VERSION ""

NS_ :

BS_:

BU_: DEBUG BMS DCM FSM PDM DIM

BO_ 100 BMS_HEARTBEAT: 1 BMS
SG_ DUMMY_VARIABLE : 0|1@1+ (1,0) [0|1] "" FSM,DCM,PDM,DIM,INV

BO_ 101 BMS_CAN_FIFO_OVERFLOW: 8 BMS
SG_ tx_overflow_count : 0|32@1+ (1,0) [0|4294967295] "" DEBUG
SG_ rx_overflow_count : 32|32@1+ (1,0) [0|4294967295] "" DEBUG

BO_ 102 BMS_STARTUP: 0 BMS

BO_ 103 BMS_WATCHDOG_TIMEOUT : 8 BMS
SG_ TASK_NAME : 0|64@1+ (1,0) [0|0] "" DEBUG

BO_ 104 BMS_NON_CRITICAL_ERRORS: 8 BMS
SG_ STACK_WATERMARK_ABOVE_THRESHOLD_TASK1HZ : 0|1@1+ (1,0) [0|1] "" DEBUG
SG_ STACK_WATERMARK_ABOVE_THRESHOLD_TASK1KHZ : 1|1@1+ (1,0) [0|1] "" DEBUG
SG_ STACK_WATERMARK_ABOVE_THRESHOLD_TASKCANRX : 2|1@1+ (1,0) [0|1] "" DEBUG
SG_ STACK_WATERMARK_ABOVE_THRESHOLD_TASKCANTX : 3|1@1+ (1,0) [0|1] "" DEBUG
SG_ WATCHDOG_TIMEOUT : 4|1@1+ (1,0) [0|1] "" DEBUG
SG_ SEGMENT_0_VOLTAGE_OUT_OF_RANGE : 6|2@1+ (1,0) [0|2] "" DEBUG
SG_ SEGMENT_1_VOLTAGE_OUT_OF_RANGE : 8|2@1+ (1,0) [0|2] "" DEBUG
SG_ SEGMENT_2_VOLTAGE_OUT_OF_RANGE : 10|2@1+ (1,0) [0|2] "" DEBUG
SG_ SEGMENT_3_VOLTAGE_OUT_OF_RANGE : 12|2@1+ (1,0) [0|2] "" DEBUG
SG_ SEGMENT_4_VOLTAGE_OUT_OF_RANGE : 14|2@1+ (1,0) [0|2] "" DEBUG
SG_ SEGMENT_5_VOLTAGE_OUT_OF_RANGE : 16|2@1+ (1,0) [0|2] "" DEBUG
SG_ PACK_VOLTAGE_OUT_OF_RANGE : 18|2@1+ (1,0) [0|2] "" DEBUG
SG_ AVERAGE_CELL_VOLTAGE_OUT_OF_RANGE : 20|2@1+ (1,0) [0|2] "" DEBUG
SG_ CELL_MONITOR_0_DIE_TEMP_OUT_OF_RANGE : 22|2@1+ (1,0) [0|2] "" DEBUG
SG_ CELL_MONITOR_1_DIE_TEMP_OUT_OF_RANGE : 24|2@1+ (1,0) [0|2] "" DEBUG
SG_ CELL_MONITOR_2_DIE_TEMP_OUT_OF_RANGE : 26|2@1+ (1,0) [0|2] "" DEBUG
SG_ CELL_MONITOR_3_DIE_TEMP_OUT_OF_RANGE : 28|2@1+ (1,0) [0|2] "" DEBUG
SG_ CELL_MONITOR_4_DIE_TEMP_OUT_OF_RANGE : 30|2@1+ (1,0) [0|2] "" DEBUG
SG_ CELL_MONITOR_5_DIE_TEMP_OUT_OF_RANGE : 32|2@1+ (1,0) [0|2] "" DEBUG
SG_ ITMP_CHARGER_HAS_OVERFLOW : 34|1@1+ (1,0) [0|1] "" DEBUG

BO_ 105 BMS_IMD: 8 BMS
SG_ Condition M : 0|3@1+ (1,0) [0|6] "" DEBUG
SG_ Seconds_Since_Power_On : 3|16@1+ (1,0) [0|255] "Seconds" DEBUG
SG_ Valid_Duty_Cycle : 19|1@1+ (1,0) [0|1] "" DEBUG
SG_ Insulation_Measurement_DCP_10Hz m1 : 20|16@1+ (1,0) [0|65535] "kOhm" DEBUG
SG_ Insulation_Measurement_DCP_20Hz m2 : 20|16@1+ (1,0) [0|65535] "kOhm" DEBUG
SG_ Speed_Start_Status_30Hz m3 : 20|16@1+ (1,0) [0|65535] "" DEBUG
SG_ OK_HS : 36|1@1+ (1,0) [0|1] "" DIM

BO_ 106 BMS_IMD_PWM_OUTPUT : 8 BMS
SG_ Duty_Cycle : 0|32@1- (1,0) [0|1E2] "%" DEBUG
SG_ Frequency : 32|32@1- (1,0) [0|1E4] "Hz" DEBUG

BO_ 107 BMS_STATE_MACHINE : 1 BMS
SG_ State : 0|8@1+ (1,0) [0|255] "" DEBUG

BO_ 108 BMS_STATE_OF_CHARGE: 4 BMS
SG_ State_Of_Charge : 0|32@1- (1,0) [0|1E2] "%" DIM

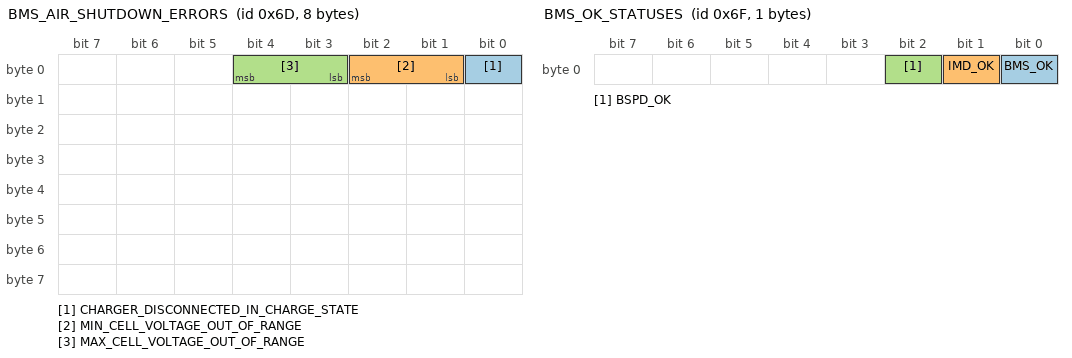
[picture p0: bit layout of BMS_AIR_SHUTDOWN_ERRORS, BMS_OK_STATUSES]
BO_ 109 BMS_AIR_SHUTDOWN_ERRORS: 8 BMS
SG_ CHARGER_DISCONNECTED_IN_CHARGE_STATE : 0|1@1+ (1,0) [0|1] "" DEBUG
SG_ MIN_CELL_VOLTAGE_OUT_OF_RANGE : 1|2@1+ (1,0) [0|2] "" DEBUG
SG_ MAX_CELL_VOLTAGE_OUT_OF_RANGE : 3|2@1+ (1,0) [0|2] "" DEBUG

BO_ 110 BMS_CHARGER: 1 BMS
SG_ Is_Connected : 0|1@1+ (1,0) [0|1] "" DEBUG

BO_ 111 BMS_OK_STATUSES: 1 BMS
SG_ BMS_OK : 0|1@1+ (1,0) [0|1] "" DEBUG
SG_ IMD_OK : 1|1@1+ (1,0) [0|1] "" DEBUG
SG_ BSPD_OK : 2|1@1+ (1,0) [0|1] "" DEBUG

BO_ 112 BMS_AIR_STATES: 1 BMS
SG_ AIR_POSITIVE : 0|1@1+ (1,0) [0|1] "" FSM,DCM,PDM
SG_ AIR_NEGATIVE : 1|1@1+ (1,0) [0|1] "" FSM,DCM,PDM

BO_ 113 BMS_MOTOR_SHUTDOWN_ERRORS: 8 BMS
SG_ DUMMY_MOTOR_SHUTDOWN : 0|1@1+ (1,0) [0|1] "" DEBUG

BO_ 114 BMS_ACCUMULATOR_MIN_AND_MAX_VOLTAGES: 8 BMS
SG_ MIN_CELL_VOLTAGE : 0|32@1+ (1,0) [3.0|4.20] "V" DEBUG
SG_ MAX_CELL_VOLTAGE : 32|32@1+ (1,0) [3.0|4.20] "V" DEBUG

BO_ 115 BMS_ACCUMULATOR_PACK: 4 BMS
SG_ PACK_VOLTAGE : 0|32@1+ (1,0) [288.0|403.2] "V" DEBUG

BO_ 116 BMS_ACCUMULATOR_AVERAGE_CELL: 4 BMS
SG_ AVERAGE_CELL_VOLTAGE : 0|32@1+ (1,0) [3.0|4.20] "V" DEBUG

BO_ 117 BMS_ACCUMULATOR_SEGMENT_0: 4 BMS
SG_ SEGMENT_0_VOLTAGE : 0|32@1+ (1,0) [48.0|67.2] "V" DEBUG

BO_ 118 BMS_ACCUMULATOR_SEGMENT_1: 4 BMS
SG_ SEGMENT_1_VOLTAGE : 0|32@1+ (1,0) [48.0|67.2] "V" DEBUG

BO_ 119 BMS_ACCUMULATOR_SEGMENT_2: 4 BMS
SG_ SEGMENT_2_VOLTAGE : 0|32@1+ (1,0) [48.0|67.2] "V" DEBUG

BO_ 120 BMS_ACCUMULATOR_SEGMENT_3: 4 BMS
SG_ SEGMENT_3_VOLTAGE : 0|32@1+ (1,0) [48.0|67.2] "V" DEBUG

BO_ 121 BMS_ACCUMULATOR_SEGMENT_4: 4 BMS
SG_ SEGMENT_4_VOLTAGE : 0|32@1+ (1,0) [48.0|67.2] "V" DEBUG

BO_ 122 BMS_ACCUMULATOR_SEGMENT_5: 4 BMS
SG_ SEGMENT_5_VOLTAGE : 0|32@1+ (1,0) [48.0|67.2] "V" DEBUG

BO_ 123 BMS_CELL_MONITOR_0: 4 BMS
SG_ CELL_MONITOR_0_DIE_TEMPERATURE : 0|32@1+ (1,0) [0.0|120.0] "degC" DEBUG

BO_ 124 BMS_CELL_MONITOR_1: 4 BMS
SG_ CELL_MONITOR_1_DIE_TEMPERATURE : 0|32@1+ (1,0) [0.0|120.0] "degC" DEBUG

BO_ 125 BMS_CELL_MONITOR_2: 4 BMS
SG_ CELL_MONITOR_2_DIE_TEMPERATURE : 0|32@1+ (1,0) [0.0|120.0] "degC" DEBUG

BO_ 126 BMS_CELL_MONITOR_3: 4 BMS
SG_ CELL_MONITOR_3_DIE_TEMPERATURE : 0|32@1+ (1,0) [0.0|120.0] "degC" DEBUG

BO_ 127 BMS_CELL_MONITOR_4: 4 BMS
SG_ CELL_MONITOR_4_DIE_TEMPERATURE : 0|32@1+ (1,0) [0.0|120.0] "degC" DEBUG

BO_ 128 BMS_CELL_MONITOR_5: 4 BMS
SG_ CELL_MONITOR_5_DIE_TEMPERATURE : 0|32@1+ (1,0) [0.0|120.0] "degC" DEBUG

BO_ 129 BMS_MAX_CELL_MONITOR: 4 BMS
SG_ MAX_CELL_MONITOR_DIE_TEMPERATURE : 0|32@1+ (1,0) [0.0|120.0] "degC" DEBUG

BO_ 200 DCM_HEARTBEAT: 1 DCM
SG_ DUMMY_VARIABLE : 0|1@1+ (1,0) [0|1] "" BMS

BO_ 201 DCM_CAN_FIFO_OVERFLOW: 8 DCM
SG_ tx_overflow_count : 0|32@1+ (1,0) [0|4294967295] "" DEBUG
SG_ rx_overflow_count : 32|32@1+ (1,0) [0|4294967295] "" DEBUG

BO_ 202 DCM_STARTUP: 0 DCM

BO_ 203 DCM_WATCHDOG_TIMEOUT : 8 DCM
SG_ TASK_NAME : 0|64@1+ (1,0) [0|0] "" DEBUG

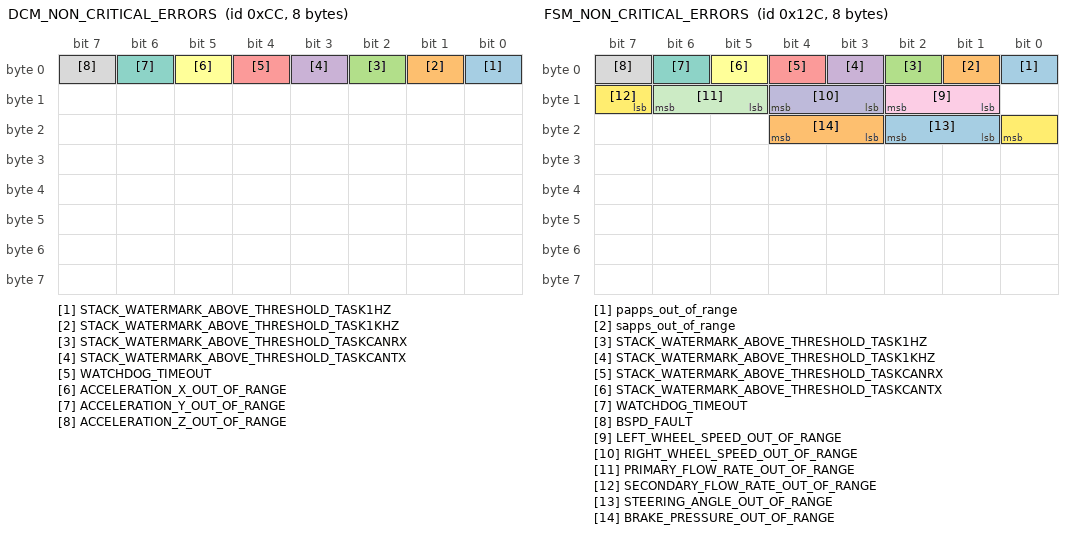
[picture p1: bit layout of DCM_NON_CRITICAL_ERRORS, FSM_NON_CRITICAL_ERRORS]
BO_ 204 DCM_NON_CRITICAL_ERRORS: 8 DCM
SG_ STACK_WATERMARK_ABOVE_THRESHOLD_TASK1HZ : 0|1@1+ (1,0) [0|1] "" DEBUG
SG_ STACK_WATERMARK_ABOVE_THRESHOLD_TASK1KHZ : 1|1@1+ (1,0) [0|1] "" DEBUG
SG_ STACK_WATERMARK_ABOVE_THRESHOLD_TASKCANRX : 2|1@1+ (1,0) [0|1] "" DEBUG
SG_ STACK_WATERMARK_ABOVE_THRESHOLD_TASKCANTX : 3|1@1+ (1,0) [0|1] "" DEBUG
SG_ WATCHDOG_TIMEOUT : 4|1@1+ (1,0) [0|1] "" DEBUG
SG_ ACCELERATION_X_OUT_OF_RANGE : 5|1@1+ (1,0) [0|1] "" DEBUG
SG_ ACCELERATION_Y_OUT_OF_RANGE : 6|1@1+ (1,0) [0|1] "" DEBUG
SG_ ACCELERATION_Z_OUT_OF_RANGE : 7|1@1+ (1,0) [0|1] "" DEBUG

BO_ 205 DCM_STATE_MACHINE : 1 DCM
SG_ State : 0|8@1+ (1,0) [0|255] "" DEBUG

BO_ 206 DCM_TORQUE_REQUEST : 4 DCM
SG_ Torque_Request : 0|32@1+ (1,0) [-3.4E038|3.4E038] "" LOGGER,INV

BO_ 207 DCM_AIR_SHUTDOWN_ERRORS: 8 DCM
SG_ DUMMY_AIR_SHUTDOWN : 0|1@1+ (1,0) [0|1] "" DEBUG

BO_ 208 DCM_MOTOR_SHUTDOWN_ERRORS: 8 DCM
SG_ DUMMY_MOTOR_SHUTDOWN : 0|1@1+ (1,0) [0|1] "" DEBUG

BO_ 209 DCM_ACCELERATION_X: 4 DCM
SG_ ACCELERATION_X : 0|32@1+ (1,0) [-30.00|30.00] "m/s^2" DEBUG

BO_ 210 DCM_ACCELERATION_Y: 4 DCM
SG_ ACCELERATION_Y : 0|32@1+ (1,0) [-30.00|30.00] "m/s^2" DEBUG

BO_ 211 DCM_ACCELERATION_Z: 4 DCM
SG_ ACCELERATION_Z : 0|32@1+ (1,0) [-30.00|30.00] "m/s^2" DEBUG

BO_ 300 FSM_NON_CRITICAL_ERRORS: 8 FSM
SG_ papps_out_of_range : 0|1@1+ (1,0) [0|1] "" DEBUG
SG_ sapps_out_of_range : 1|1@1+ (1,0) [0|1] "" DEBUG
SG_ STACK_WATERMARK_ABOVE_THRESHOLD_TASK1HZ : 2|1@1+ (1,0) [0|1] "" DEBUG
SG_ STACK_WATERMARK_ABOVE_THRESHOLD_TASK1KHZ : 3|1@1+ (1,0) [0|1] "" DEBUG
SG_ STACK_WATERMARK_ABOVE_THRESHOLD_TASKCANRX : 4|1@1+ (1,0) [0|1] "" DEBUG
SG_ STACK_WATERMARK_ABOVE_THRESHOLD_TASKCANTX : 5|1@1+ (1,0) [0|1] "" DEBUG
SG_ WATCHDOG_TIMEOUT : 6|1@1+ (1,0) [0|1] "" DEBUG
SG_ BSPD_FAULT : 7|1@1+ (1,0) [0|1] "" DIM
SG_ LEFT_WHEEL_SPEED_OUT_OF_RANGE: 9|2@1+ (1,0) [0|2] "" DEBUG
SG_ RIGHT_WHEEL_SPEED_OUT_OF_RANGE: 11|2@1+ (1,0) [0|2] ""  DEBUG
SG_ PRIMARY_FLOW_RATE_OUT_OF_RANGE: 13|2@1+ (1,0) [0|2] "" DEBUG
SG_ SECONDARY_FLOW_RATE_OUT_OF_RANGE: 15|2@1+ (1,0) [0|2] "" DEBUG
SG_ STEERING_ANGLE_OUT_OF_RANGE: 17|2@1+ (1,0) [0|2] "" DEBUG
SG_ BRAKE_PRESSURE_OUT_OF_RANGE: 19|2@1+ (1,0) [0|2] "" DEBUG

BO_ 301 FSM_HEARTBEAT: 1 FSM
SG_ DUMMY_VARIABLE : 0|1@1+ (1,0) [0|1] "" BMS

BO_ 302 FSM_CAN_FIFO_OVERFLOW: 8 FSM
SG_ tx_overflow_count : 0|32@1+ (1,0) [0|1] "" DEBUG
SG_ rx_overflow_count : 32|32@1+ (1,0) [0|1] "" DEBUG

BO_ 303 FSM_STARTUP: 0 FSM

BO_ 304 FSM_WATCHDOG_TIMEOUT : 8 FSM
SG_ TASK_NAME : 0|64@1+ (1,0) [0|0] "" DEBUG

BO_ 305 FSM_STATE_MACHINE : 1 FSM
SG_ State : 0|8@1+ (1,0) [0|255] "" DEBUG

BO_ 306 FSM_AIR_SHUTDOWN: 0 FSM

BO_ 307 FSM_FLOW_METER: 8 FSM
SG_ Primary_Flow_Rate : 0|32@1+ (1,0) [0|100] "L/min" DEBUG
SG_ Secondary_Flow_Rate : 32|32@1+ (1,0) [0|100] "L/min" DEBUG

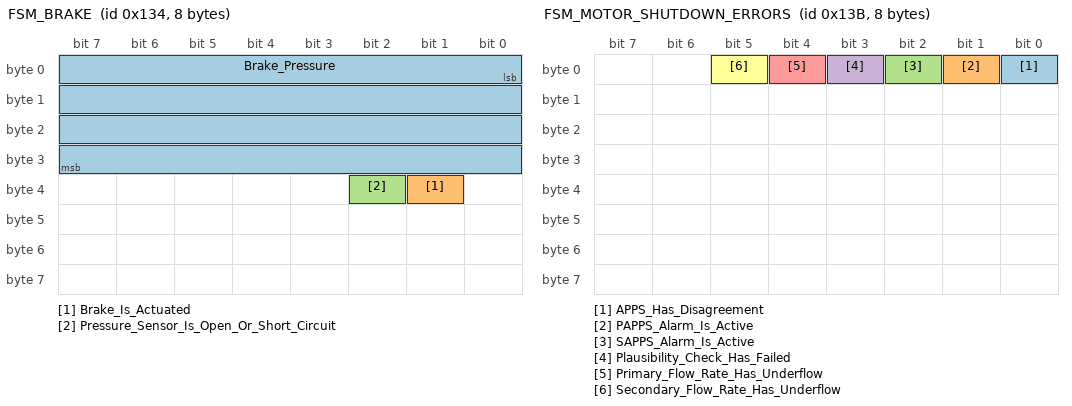
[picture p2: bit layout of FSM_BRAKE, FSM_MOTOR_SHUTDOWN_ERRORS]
BO_ 308 FSM_BRAKE: 8 FSM
SG_ Brake_Pressure: 0|32@1+ (1,0) [0|2500] "psi" DEBUG
SG_ Brake_Is_Actuated: 33|1@1+ (1,0) [0|1] "" DCM
SG_ Pressure_Sensor_Is_Open_Or_Short_Circuit: 34|1@1+ (1,0) [0|1] "" DEBUG

BO_ 309 FSM_WHEEL_SPEED_SENSOR: 8 FSM
SG_ Left_Wheel_Speed : 0|32@1+ (1,0) [0|150] "km/h" DCM
SG_ Right_Wheel_Speed : 32|32@1+ (1,0) [0|150] "km/h" DCM

BO_ 310 FSM_AIR_SHUTDOWN_ERRORS: 8 FSM
SG_ DUMMY_AIR_SHUTDOWN : 0|1@1+ (1,0) [0|1] "" DEBUG

BO_ 311 FSM_STEERING_ANGLE_SENSOR: 4 FSM
SG_ Steering_Angle : 0|32@1+ (1,0) [-110|110] "deg" DCM

BO_ 313 FSM_PRIMARY_APPS: 4 FSM
SG_ Papps_Mapped_Pedal_Percentage : 0|32@1+ (1,0) [0|100] "%" DEBUG

BO_ 314 FSM_SECONDARY_APPS: 4 FSM
SG_ Sapps_Mapped_Pedal_Percentage : 0|32@1+ (1,0) [0|100] "%" DEBUG

BO_ 315 FSM_MOTOR_SHUTDOWN_ERRORS: 8 FSM
SG_ APPS_Has_Disagreement : 0|1@1+ (1,0) [0|1] "" DEBUG
SG_ PAPPS_Alarm_Is_Active : 1|1@1+ (1,0) [0|1] "" DEBUG
SG_ SAPPS_Alarm_Is_Active : 2|1@1+ (1,0) [0|1] "" DEBUG
SG_ Plausibility_Check_Has_Failed : 3|1@1+ (1,0) [0|1] "" DEBUG
SG_ Primary_Flow_Rate_Has_Underflow : 4|1@1+ (1,0) [0|1] "" DEBUG
SG_ Secondary_Flow_Rate_Has_Underflow : 5|1@1+ (1,0) [0|1] "" DEBUG

BO_ 316 FSM_PEDAL_POSITION: 4 FSM
SG_ Mapped_Pedal_Percentage: 0|32@1+ (1,0) [0|100] "%" DCM

BO_ 400 PDM_NON_CRITICAL_ERRORS: 8 PDM
SG_ MISSING_HEARTBEAT : 0|1@1+ (1,0) [0|1] "" DEBUG
SG_ BOOST_PGOOD_FAULT : 1|1@1+ (1,0) [0|1] "" DEBUG
SG_ CHARGER_FAULT : 3|1@1+ (1,0) [0|1] "" DEBUG
SG_ EFUSE_FAULT : 4|1@1+ (1,0) [0|1] "" DEBUG
SG_ STACK_WATERMARK_ABOVE_THRESHOLD_TASK1HZ : 5|1@1+ (1,0) [0|1] "" DEBUG
SG_ STACK_WATERMARK_ABOVE_THRESHOLD_TASK1KHZ : 6|1@1+ (1,0) [0|1] "" DEBUG
SG_ STACK_WATERMARK_ABOVE_THRESHOLD_TASKCANRX : 7|1@1+ (1,0) [0|1] "" DEBUG
SG_ STACK_WATERMARK_ABOVE_THRESHOLD_TASKCANTX : 8|1@1+ (1,0) [0|1] "" DEBUG
SG_ WATCHDOG_TIMEOUT : 9|1@1+ (1,0) [0|1] "" DEBUG
SG_ VBAT_VOLTAGE_OUT_OF_RANGE : 10|2@1+ (1,0) [0|2] "" DEBUG
SG_ _24V_AUX_VOLTAGE_OUT_OF_RANGE : 12|2@1+ (1,0) [0|2] "" DEBUG
SG_ _24V_ACC_VOLTAGE_OUT_OF_RANGE : 14|2@1+ (1,0) [0|2] "" DEBUG
SG_ AUX1_CURRENT_OUT_OF_RANGE : 16|2@1+ (1,0) [0|2] "" DEBUG
SG_ AUX2_CURRENT_OUT_OF_RANGE : 18|2@1+ (1,0) [0|2] "" DEBUG
SG_ LEFT_INVERTER_CURRENT_OUT_OF_RANGE : 20|2@1+ (1,0) [0|2] "" DEBUG
SG_ RIGHT_INVERTER_CURRENT_OUT_OF_RANGE : 22|2@1+ (1,0) [0|2] "" DEBUG
SG_ ENERGY_METER_CURRENT_OUT_OF_RANGE : 24|2@1+ (1,0) [0|2] "" DEBUG
SG_ CAN_CURRENT_OUT_OF_RANGE : 26|2@1+ (1,0) [0|2] "" DEBUG
SG_ AIR_SHUTDOWN_CURRENT_OUT_OF_RANGE : 28|2@1+ (1,0) [0|2] "" DEBUG

BO_ 401 PDM_HEARTBEAT: 1 PDM
SG_ DUMMY_VARIABLE : 0|1@1+ (1,0) [0|1] "" BMS

BO_ 402 PDM_CAN_FIFO_OVERFLOW: 8 PDM
SG_ tx_overflow_count : 0|32@1+ (1,0) [0|4294967295] "" DEBUG
SG_ rx_overflow_count : 32|32@1+ (1,0) [0|4294967295] "" DEBUG

BO_ 403 PDM_STARTUP: 0 PDM

BO_ 404 PDM_AIR_SHUTDOWN_ERRORS: 8 PDM
SG_ DUMMY_AIR_SHUTDOWN : 0|1@1+ (1,0) [0|1] "" DEBUG

BO_ 405 PDM_MOTOR_SHUTDOWN_ERRORS: 8 PDM
SG_ DUMMY_MOTOR_SHUTDOWN : 0|1@1+ (1,0) [0|1] "" DEBUG

BO_ 406 PDM_AUX1_AUX2_CURRENT: 8 PDM
SG_ Auxiliary1_Current : 0|32@1- (1,0) [0|1E2] "A" DEBUG
SG_ Auxiliary2_Current : 32|32@1- (1,0) [0|1E2] "A" DEBUG

BO_ 407 PDM_ENERGY_METER_CURRENT: 8 PDM
SG_ Energy_Meter_Current : 0|32@1- (1,0) [0|1E2] "A" DEBUG
SG_ Unused : 32|32@1- (1,0) [0|1E2] "A" DEBUG

BO_ 408 PDM_AIRSHDN_CANGLV_CURRENT: 8 PDM
SG_ CAN_Current : 0|32@1- (1,0) [0|1E2] "A" DEBUG
SG_ AIR_Shutdown_Current : 32|32@1- (1,0) [0|1E2] "A" DEBUG

BO_ 409 PDM_INVERTER_CURRENT: 8 PDM
SG_ Left_Inverter_Current : 0|32@1- (1,0) [0|1E2] "A" DEBUG
SG_ Right_Inverter_Current : 32|32@1- (1,0) [0|1E2] "A" DEBUG

BO_ 410 PDM_24V: 8 PDM
SG_ _24V_AUX : 0|32@1- (1,0) [0|1E2] "V" DEBUG
SG_ _24V_ACC: 32|32@1- (1,0) [0|1E2] "V" DEBUG

BO_ 411 PDM_VBAT: 4 PDM
SG_ VBAT : 0|32@1- (1,0) [0|1E2] "V" DEBUG

BO_ 412 PDM_WATCHDOG_TIMEOUT: 8 PDM
SG_ TASK_NAME : 0|64@1+ (1,0) [0|0] "" DEBUG

BO_ 413 PDM_STATE_MACHINE : 1 PDM
SG_ State : 0|8@1+ (1,0) [0|255] "" DEBUG

BO_ 500 DIM_HEARTBEAT: 1 DIM
SG_ DUMMY_VARIABLE : 0|1@1+ (1,0) [0|1] "" FSM,DCM,PDM,BMS

BO_ 501 DIM_CAN_FIFO_OVERFLOW: 8 DIM
SG_ tx_overflow_count : 0|32@1+ (1,0) [0|4294967295] "" DEBUG
SG_ rx_overflow_count : 32|32@1+ (1,0) [0|4294967295] "" DEBUG

BO_ 502 DIM_STARTUP: 0 DIM

BO_ 503 DIM_STATE_MACHINE : 1 DIM
SG_ State : 0|8@1+ (1,0) [0|255] "" DEBUG

BO_ 504 DIM_WATCHDOG_TIMEOUT: 8 DIM
SG_ TASK_NAME : 0|64@1+ (1,0) [0|0] "" DEBUG

BO_ 505 DIM_REGEN_PADDLE: 8 DIM
SG_ Raw_Paddle_Position : 0|32@1+ (1,0) [0|100] "%" DEBUG
SG_ Mapped_Paddle_Position : 32|32@1+ (1,0) [0|100] "%" DCM

BO_ 506 DIM_DRIVE_MODE_SWITCH: 1 DIM
SG_ Drive_Mode : 0|3@1+ (1,0) [0|5] "" DCM

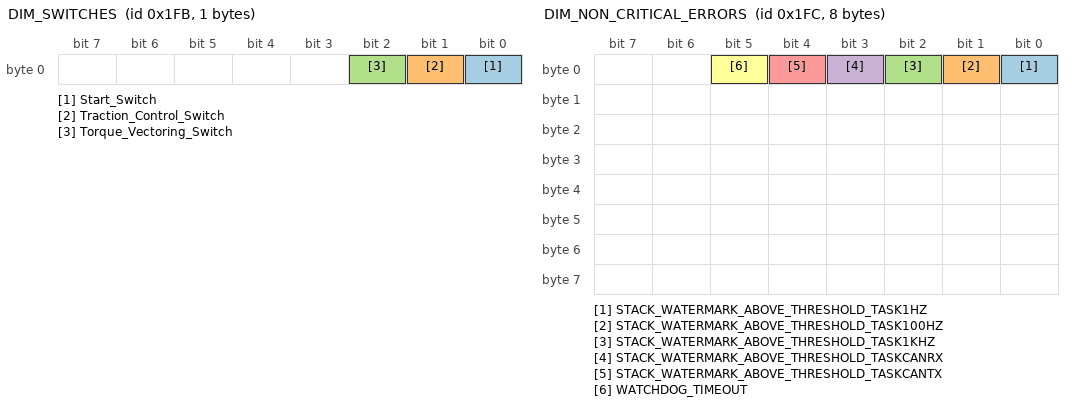
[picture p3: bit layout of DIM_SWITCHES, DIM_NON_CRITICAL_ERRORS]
BO_ 507 DIM_SWITCHES: 1 DIM
SG_ Start_Switch : 0|1@1+ (1,0) [0|1] "" DCM
SG_ Traction_Control_Switch : 1|1@1+ (1,0) [0|1] "" DCM
SG_ Torque_Vectoring_Switch : 2|1@1+ (1,0) [0|1] "" DCM

BO_ 508 DIM_NON_CRITICAL_ERRORS: 8 DIM
SG_ STACK_WATERMARK_ABOVE_THRESHOLD_TASK1HZ : 0|1@1+ (1,0) [0|1] "" LOGGER
SG_ STACK_WATERMARK_ABOVE_THRESHOLD_TASK100HZ : 1|1@1+ (1,0) [0|1] "" LOGGER
SG_ STACK_WATERMARK_ABOVE_THRESHOLD_TASK1KHZ : 2|1@1+ (1,0) [0|1] "" LOGGER
SG_ STACK_WATERMARK_ABOVE_THRESHOLD_TASKCANRX : 3|1@1+ (1,0) [0|1] "" LOGGER
SG_ STACK_WATERMARK_ABOVE_THRESHOLD_TASKCANTX : 4|1@1+ (1,0) [0|1] "" LOGGER
SG_ WATCHDOG_TIMEOUT : 5|1@1+ (1,0) [0|1] "" LOGGER

BO_ 509 DIM_AIR_SHUTDOWN_ERRORS: 8 DIM
SG_ DUMMY_AIR_SHUTDOWN : 0|1@1+ (1,0) [0|1] "" DEBUG

BO_ 510 DIM_MOTOR_SHUTDOWN_ERRORS: 8 DIM
SG_ DUMMY_MOTOR_SHUTDOWN : 0|1@1+ (1,0) [0|1] "" DEBUG

BO_ 600 INV_HEARTBEAT: 1 INV
SG_ DUMMY_VARIABLE : 0|1@1+ (1,0) [0|1] "" FSM,DCM,PDM,BMS,DIM

BO_ 601 INV_CAN_FIFO_OVERFLOW: 8 INV
SG_ tx_overflow_count : 0|32@1+ (1,0) [0|4294967295] "" DEBUG
SG_ rx_overflow_count : 32|32@1+ (1,0) [0|4294967295] "" DEBUG

BO_ 602 INV_STARTUP: 0 INV

BO_ 603 INV_STATE_MACHINE : 2 INV
SG_ State : 0|8@1+ (1,0) [0|255] "" DEBUG
SG_ Command : 8|8@1+ (1,0) [0|255] "" DEBUG

BO_ 604 INV_WATCHDOG_TIMEOUT: 8 INV
SG_ TASK_NAME : 0|64@1+ (1,0) [0|0] "" DEBUG

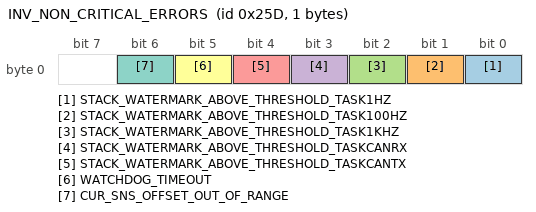
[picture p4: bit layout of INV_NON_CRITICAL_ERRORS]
BO_ 605 INV_NON_CRITICAL_ERRORS: 1 INV
SG_ STACK_WATERMARK_ABOVE_THRESHOLD_TASK1HZ : 0|1@1+ (1,0) [0|1] "" LOGGER
SG_ STACK_WATERMARK_ABOVE_THRESHOLD_TASK100HZ : 1|1@1+ (1,0) [0|1] "" LOGGER
SG_ STACK_WATERMARK_ABOVE_THRESHOLD_TASK1KHZ : 2|1@1+ (1,0) [0|1] "" LOGGER
SG_ STACK_WATERMARK_ABOVE_THRESHOLD_TASKCANRX : 3|1@1+ (1,0) [0|1] "" LOGGER
SG_ STACK_WATERMARK_ABOVE_THRESHOLD_TASKCANTX : 4|1@1+ (1,0) [0|1] "" LOGGER
SG_ WATCHDOG_TIMEOUT : 5|1@1+ (1,0) [0|1] "" LOGGER
SG_ CUR_SNS_OFFSET_OUT_OF_RANGE : 6|1@1+ (1,0) [0|1] "" LOGGER

BO_ 606 INV_AIR_SHUTDOWN_ERRORS: 8 INV
SG_ DUMMY_AIR_SHUTDOWN : 0|1@1+ (1,0) [0|1] "" DEBUG

BO_ 607 INV_MOTOR_SHUTDOWN_ERRORS: 8 INV
SG_ DUMMY_MOTOR_SHUTDOWN : 0|1@1+ (1,0) [0|1] "" DEBUG

BA_DEF_  "BusType" STRING ;
BA_DEF_ BO_  "GenMsgCycleTime" INT 0 65535;
BA_DEF_ SG_  "GenSigStartValue" INT 0 2147483647;

BA_DEF_DEF_  "BusType" "CAN";
BA_DEF_DEF_  "GenMsgCycleTime" 0;
BA_DEF_DEF_  "GenSigStartValue" 0;

BA_ "GenMsgCycleTime" BO_ 100 100;
BA_ "GenMsgCycleTime" BO_ 101 5000;
BA_ "GenMsgCycleTime" BO_ 104 1000;
BA_ "GenMsgCycleTime" BO_ 105 1000;
BA_ "GenMsgCycleTime" BO_ 106 1000;
BA_ "GenMsgCycleTime" BO_ 107 10;
BA_ "GenMsgCycleTime" BO_ 108 10;
BA_ "GenMsgCycleTime" BO_ 109 1000;
BA_ "GenMsgCycleTime" BO_ 110 1000;
BA_ "GenMsgCycleTime" BO_ 111 10;
BA_ "GenMsgCycleTime" BO_ 112 10;
BA_ "GenMsgCycleTime" BO_ 113 1000;
BA_ "GenMsgCycleTime" BO_ 114 10;
BA_ "GenMsgCycleTime" BO_ 115 10;
BA_ "GenMsgCycleTime" BO_ 116 10;
BA_ "GenMsgCycleTime" BO_ 117 10;
BA_ "GenMsgCycleTime" BO_ 118 10;
BA_ "GenMsgCycleTime" BO_ 119 10;
BA_ "GenMsgCycleTime" BO_ 120 10;
BA_ "GenMsgCycleTime" BO_ 121 10;
BA_ "GenMsgCycleTime" BO_ 122 10;
BA_ "GenMsgCycleTime" BO_ 123 1000;
BA_ "GenMsgCycleTime" BO_ 124 1000;
BA_ "GenMsgCycleTime" BO_ 125 1000;
BA_ "GenMsgCycleTime" BO_ 126 1000;
BA_ "GenMsgCycleTime" BO_ 127 1000;
BA_ "GenMsgCycleTime" BO_ 128 1000;
BA_ "GenMsgCycleTime" BO_ 129 1000;
BA_ "GenMsgCycleTime" BO_ 200 100;
BA_ "GenMsgCycleTime" BO_ 201 5000;
BA_ "GenMsgCycleTime" BO_ 204 1000;
BA_ "GenMsgCycleTime" BO_ 205 10;
BA_ "GenMsgCycleTime" BO_ 206 10;
BA_ "GenMsgCycleTime" BO_ 207 1000;
BA_ "GenMsgCycleTime" BO_ 208 1000;
BA_ "GenMsgCycleTime" BO_ 209 10;
BA_ "GenMsgCycleTime" BO_ 210 10;
BA_ "GenMsgCycleTime" BO_ 211 10;
BA_ "GenMsgCycleTime" BO_ 300 1000;
BA_ "GenMsgCycleTime" BO_ 301 100;
BA_ "GenMsgCycleTime" BO_ 302 5000;
BA_ "GenMsgCycleTime" BO_ 305 10;
BA_ "GenMsgCycleTime" BO_ 307 1000;
BA_ "GenMsgCycleTime" BO_ 308 10;
BA_ "GenMsgCycleTime" BO_ 309 10;
BA_ "GenMsgCycleTime" BO_ 310 1000;
BA_ "GenMsgCycleTime" BO_ 311 10;
BA_ "GenMsgCycleTime" BO_ 313 10;
BA_ "GenMsgCycleTime" BO_ 314 10;
BA_ "GenMsgCycleTime" BO_ 315 1000;
BA_ "GenMsgCycleTime" BO_ 316 100;
BA_ "GenMsgCycleTime" BO_ 400 1000;
BA_ "GenMsgCycleTime" BO_ 401 100;
BA_ "GenMsgCycleTime" BO_ 402 5000;
BA_ "GenMsgCycleTime" BO_ 404 1000;
BA_ "GenMsgCycleTime" BO_ 405 1000;
BA_ "GenMsgCycleTime" BO_ 406 1000;
BA_ "GenMsgCycleTime" BO_ 407 1000;
BA_ "GenMsgCycleTime" BO_ 408 1000;
BA_ "GenMsgCycleTime" BO_ 409 1000;
BA_ "GenMsgCycleTime" BO_ 410 1000;
BA_ "GenMsgCycleTime" BO_ 411 1000;
BA_ "GenMsgCycleTime" BO_ 413 10;
BA_ "GenMsgCycleTime" BO_ 500 100;
BA_ "GenMsgCycleTime" BO_ 501 5000;
BA_ "GenMsgCycleTime" BO_ 503 10;
BA_ "GenMsgCycleTime" BO_ 505 10;
BA_ "GenMsgCycleTime" BO_ 506 10;
BA_ "GenMsgCycleTime" BO_ 507 10;
BA_ "GenMsgCycleTime" BO_ 508 1000;
BA_ "GenMsgCycleTime" BO_ 509 1000;
BA_ "GenMsgCycleTime" BO_ 510 1000;
BA_ "GenMsgCycleTime" BO_ 600 100;
BA_ "GenMsgCycleTime" BO_ 601 5000;
BA_ "GenMsgCycleTime" BO_ 603 10;
BA_ "GenMsgCycleTime" BO_ 605 1000;
BA_ "GenMsgCycleTime" BO_ 606 1000;
BA_ "GenMsgCycleTime" BO_ 607 1000;

SIG_VALTYPE_ 106 Duty_Cycle : 1;
SIG_VALTYPE_ 106 Frequency : 1;
SIG_VALTYPE_ 108 State_Of_Charge : 1;
SIG_VALTYPE_ 114 MIN_CELL_VOLTAGE : 1;
SIG_VALTYPE_ 114 MAX_CELL_VOLTAGE : 1;
SIG_VALTYPE_ 115 PACK_VOLTAGE : 1;
SIG_VALTYPE_ 116 AVERAGE_CELL_VOLTAGE : 1;
SIG_VALTYPE_ 117 SEGMENT_0_VOLTAGE : 1;
SIG_VALTYPE_ 118 SEGMENT_1_VOLTAGE : 1;
SIG_VALTYPE_ 119 SEGMENT_2_VOLTAGE : 1;
SIG_VALTYPE_ 120 SEGMENT_3_VOLTAGE : 1;
SIG_VALTYPE_ 121 SEGMENT_4_VOLTAGE : 1;
SIG_VALTYPE_ 122 SEGMENT_5_VOLTAGE : 1;
SIG_VALTYPE_ 123 CELL_MONITOR_0_DIE_TEMPERATURE : 1;
SIG_VALTYPE_ 124 CELL_MONITOR_1_DIE_TEMPERATURE : 1;
SIG_VALTYPE_ 125 CELL_MONITOR_2_DIE_TEMPERATURE : 1;
SIG_VALTYPE_ 126 CELL_MONITOR_3_DIE_TEMPERATURE : 1;
SIG_VALTYPE_ 127 CELL_MONITOR_4_DIE_TEMPERATURE : 1;
SIG_VALTYPE_ 128 CELL_MONITOR_5_DIE_TEMPERATURE : 1;
SIG_VALTYPE_ 129 MAX_CELL_MONITOR_DIE_TEMPERATURE : 1;
SIG_VALTYPE_ 206 Torque_Request : 1;
SIG_VALTYPE_ 209 ACCELERATION_X : 1;
SIG_VALTYPE_ 210 ACCELERATION_Y : 1;
SIG_VALTYPE_ 211 ACCELERATION_Z : 1;
SIG_VALTYPE_ 307 Primary_Flow_Rate: 1;
SIG_VALTYPE_ 307 Secondary_Flow_Rate: 1;
SIG_VALTYPE_ 308 Brake_Pressure: 1;
SIG_VALTYPE_ 309 Left_Wheel_Speed: 1;
SIG_VALTYPE_ 309 Right_Wheel_Speed: 1;
SIG_VALTYPE_ 311 Steering_Angle: 1;
SIG_VALTYPE_ 313 Papps_Mapped_Pedal_Percentage : 1;
SIG_VALTYPE_ 314 Sapps_Mapped_Pedal_Percentage : 1;
SIG_VALTYPE_ 316 Mapped_Pedal_Percentage : 1;
SIG_VALTYPE_ 406 Auxiliary1_Current : 1;
SIG_VALTYPE_ 406 Auxiliary2_Current : 1;
SIG_VALTYPE_ 407 Energy_Meter_Current : 1;
SIG_VALTYPE_ 408 AIR_Shutdown_Current : 1;
SIG_VALTYPE_ 408 CAN_Current : 1;
SIG_VALTYPE_ 409 Left_Inverter_Current : 1;
SIG_VALTYPE_ 409 Right_Inverter_Current : 1;
SIG_VALTYPE_ 410 _24V_AUX : 1;
SIG_VALTYPE_ 410 _24V_ACC : 1;
SIG_VALTYPE_ 411 VBAT : 1;

VAL_ 104 SEGMENT_0_VOLTAGE_OUT_OF_RANGE 0 "OK" 1 "UNDERFLOW" 2 "OVERFLOW";
VAL_ 104 SEGMENT_1_VOLTAGE_OUT_OF_RANGE 0 "OK" 1 "UNDERFLOW" 2 "OVERFLOW";
VAL_ 104 SEGMENT_2_VOLTAGE_OUT_OF_RANGE 0 "OK" 1 "UNDERFLOW" 2 "OVERFLOW";
VAL_ 104 SEGMENT_3_VOLTAGE_OUT_OF_RANGE 0 "OK" 1 "UNDERFLOW" 2 "OVERFLOW";
VAL_ 104 SEGMENT_4_VOLTAGE_OUT_OF_RANGE 0 "OK" 1 "UNDERFLOW" 2 "OVERFLOW";
VAL_ 104 SEGMENT_5_VOLTAGE_OUT_OF_RANGE 0 "OK" 1 "UNDERFLOW" 2 "OVERFLOW";
VAL_ 104 PACK_VOLTAGE_OUT_OF_RANGE 0 "OK" 1 "UNDERFLOW" 2 "OVERFLOW";
VAL_ 104 AVERAGE_CELL_VOLTAGE_OUT_OF_RANGE 0 "OK" 1 "UNDERFLOW" 2 "OVERFLOW";
VAL_ 104 CELL_MONITOR_0_DIE_TEMP_OUT_OF_RANGE 0 "OK" 1 "UNDERFLOW" 2 "OVERFLOW";
VAL_ 104 CELL_MONITOR_1_DIE_TEMP_OUT_OF_RANGE 0 "OK" 1 "UNDERFLOW" 2 "OVERFLOW";
VAL_ 104 CELL_MONITOR_2_DIE_TEMP_OUT_OF_RANGE 0 "OK" 1 "UNDERFLOW" 2 "OVERFLOW";
VAL_ 104 CELL_MONITOR_3_DIE_TEMP_OUT_OF_RANGE 0 "OK" 1 "UNDERFLOW" 2 "OVERFLOW";
VAL_ 104 CELL_MONITOR_4_DIE_TEMP_OUT_OF_RANGE 0 "OK" 1 "UNDERFLOW" 2 "OVERFLOW";
VAL_ 104 CELL_MONITOR_5_DIE_TEMP_OUT_OF_RANGE 0 "OK" 1 "UNDERFLOW" 2 "OVERFLOW";
VAL_ 104 ITMP_CHARGER_HAS_OVERFLOW 0 "FALSE" 1 "TRUE";
VAL_ 105 Condition 0 "IMD_SHORT_CIRCUIT" 1 "IMD_NORMAL" 2 "IMD_UNDERVOLTAGE_DETECTED" 3 "IMD_SST" 4 "IMD_DEVICE_ERROR" 5 "IMD_EARTH_FAULT" 6 "IMD_INVALID";
VAL_ 105 OK_HS 0 "NO FAULT" 1 "FAULT";
VAL_ 107 State 0 "INIT" 1 "AIR_OPEN" 2 "PRE_CHARGE" 3 "CHARGE" 4 "DRIVE" 5 "FAULT";
VAL_ 109 CHARGER_DISCONNECTED_IN_CHARGE_STATE  0 "FALSE" 1 "TRUE";
VAL_ 109 MIN_CELL_VOLTAGE_OUT_OF_RANGE 0 "OK" 1 "UNDERFLOW" 2 "OVERFLOW";
VAL_ 109 MAX_CELL_VOLTAGE_OUT_OF_RANGE 0 "OK" 1 "UNDERFLOW" 2 "OVERFLOW";
VAL_ 112 AIR_POSITIVE 0 "OPEN" 1 "CLOSED";
VAL_ 112 AIR_NEGATIVE 0 "OPEN" 1 "CLOSED";

VAL_ 123 SEGMENT_0_VOLTAGE_OUT_OF_RANGE 0 "OK" 1 "UNDERFLOW" 2 "OVERFLOW";
VAL_ 123 SEGMENT_1_VOLTAGE_OUT_OF_RANGE 0 "OK" 1 "UNDERFLOW" 2 "OVERFLOW";
VAL_ 123 SEGMENT_2_VOLTAGE_OUT_OF_RANGE 0 "OK" 1 "UNDERFLOW" 2 "OVERFLOW";
VAL_ 123 SEGMENT_3_VOLTAGE_OUT_OF_RANGE 0 "OK" 1 "UNDERFLOW" 2 "OVERFLOW";
VAL_ 123 SEGMENT_4_VOLTAGE_OUT_OF_RANGE 0 "OK" 1 "UNDERFLOW" 2 "OVERFLOW";
VAL_ 123 SEGMENT_5_VOLTAGE_OUT_OF_RANGE 0 "OK" 1 "UNDERFLOW" 2 "OVERFLOW";
VAL_ 123 PACK_VOLTAGE_OUT_OF_RANGE 0 "OK" 1 "UNDERFLOW" 2 "OVERFLOW";
VAL_ 123 AVERAGE_CELL_VOLTAGE_OUT_OF_RANGE 0 "OK" 1 "UNDERFLOW" 2 "OVERFLOW";

VAL_ 204 ACCELERATION_X_OUT_OF_RANGE 0 "OK" 1 "UNDERFLOW" 2 "OVERFLOW";
VAL_ 204 ACCELERATION_Y_OUT_OF_RANGE 0 "OK" 1 "UNDERFLOW" 2 "OVERFLOW";
VAL_ 204 ACCELERATION_Z_OUT_OF_RANGE 0 "OK" 1 "UNDERFLOW" 2 "OVERFLOW";

VAL_ 205 State 0 "INIT" 1 "DRIVE" 2 "FAULT";
VAL_ 300 LEFT_WHEEL_SPEED_OUT_OF_RANGE 0 "OK" 1 "UNDERFLOW" 2 "OVERFLOW";
VAL_ 300 RIGHT_WHEEL_SPEED_OUT_OF_RANGE 0 "OK" 1 "UNDERFLOW" 2 "OVERFLOW";
VAL_ 300 PRIMARY_FLOW_RATE_OUT_OF_RANGE 0 "OK" 1 "UNDERFLOW" 2 "OVERFLOW";
VAL_ 300 SECONDARY_FLOW_RATE_OUT_OF_RANGE 0 "OK" 1 "UNDERFLOW" 2 "OVERFLOW";
VAL_ 300 STEERING_ANGLE_OUT_OF_RANGE 0 "OK" 1 "UNDERFLOW" 2 "OVERFLOW";
VAL_ 300 BRAKE_PRESSURE_OUT_OF_RANGE 0 "OK" 1 "UNDERFLOW" 2 "OVERFLOW";
VAL_ 305 State 0 "AIR_OPEN" 1 "AIR_CLOSED";
VAL_ 308 Brake_Is_Actuated 0 "FALSE" 1 "TRUE";
VAL_ 308 Pressure_Sensor_Is_Open_Or_Short_Circuit 0 "FALSE" 1 "TRUE";
VAL_ 315 APPS_Has_Disagreement 0 "FALSE" 1 "TRUE";
VAL_ 315 PAPPS_Alarm_Is_Active 0 "FALSE" 1 "TRUE";
VAL_ 315 SAPPS_Alarm_Is_Active 0 "FALSE" 1 "TRUE";
VAL_ 315 Plausibility_Check_Has_Failed 0 "FALSE" 1 "TRUE";
VAL_ 315 Primary_Flow_Rate_Has_Underflow 0 "FALSE" 1 "TRUE";
VAL_ 315 Secondary_Flow_Rate_Has_Underflow 0 "FALSE" 1 "TRUE";
VAL_ 400 VBAT_VOLTAGE_OUT_OF_RANGE 0 "OK" 1 "UNDERFLOW" 2 "OVERFLOW";
VAL_ 400 _24V_AUX_VOLTAGE_OUT_OF_RANGE 0 "OK" 1 "UNDERFLOW" 2 "OVERFLOW";
VAL_ 400 _24V_ACC_VOLTAGE_OUT_OF_RANGE 0 "OK" 1 "UNDERFLOW" 2 "OVERFLOW";
VAL_ 400 AUX1_CURRENT_OUT_OF_RANGE 0 "OK" 1 "UNDERFLOW" 2 "OVERFLOW";
VAL_ 400 AUX2_CURRENT_OUT_OF_RANGE 0 "OK" 1 "UNDERFLOW" 2 "OVERFLOW";
VAL_ 400 LEFT_INVERTER_CURRENT_OUT_OF_RANGE 0 "OK" 1 "UNDERFLOW" 2 "OVERFLOW";
VAL_ 400 RIGHT_INVERTER_CURRENT_OUT_OF_RANGE 0 "OK" 1 "UNDERFLOW" 2 "OVERFLOW";
VAL_ 400 ENERGY_METER_CURRENT_OUT_OF_RANGE 0 "OK" 1 "UNDERFLOW" 2 "OVERFLOW";
VAL_ 400 CAN_CURRENT_OUT_OF_RANGE 0 "OK" 1 "UNDERFLOW" 2 "OVERFLOW";
VAL_ 400 AIR_SHUTDOWN_CURRENT_OUT_OF_RANGE 0 "OK" 1 "UNDERFLOW" 2 "OVERFLOW";
VAL_ 413 State 0 "INIT" 1 "AIR_OPEN" 2 "AIR_CLOSED";
VAL_ 503 State 0 "DRIVE";
VAL_ 506 Drive_Mode 0 "DRIVE_MODE_1" 1 "DRIVE_MODE_2" 2 "DRIVE_MODE_3" 3 "DRIVE_MODE_4" 4 "DRIVE_MODE_5" 5 "DRIVE_MODE_INVALID";
VAL_ 507 Start_Switch 0 "OFF" 1 "ON";
VAL_ 507 Traction_Control_Switch 0 "OFF" 1 "ON";
VAL_ 507 Torque_Vectoring_Switch  0 "OFF" 1 "ON";
VAL_ 603 State 0 "INIT" 1 "DRIVE" 2 "FAULT";
VAL_ 603 State_Command 0 "INIT" 1 "DRIVE" 2 "FAULT";
